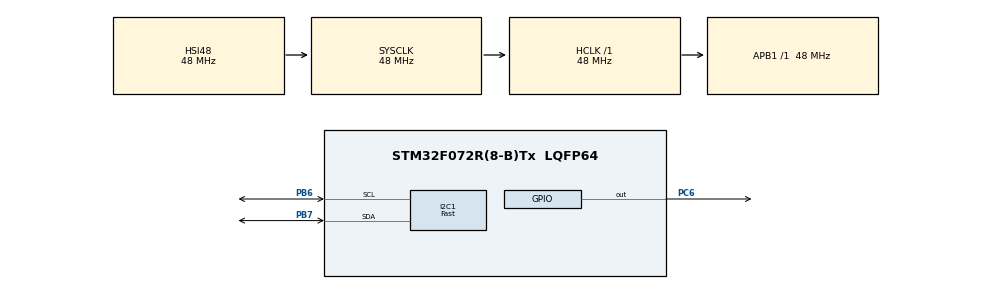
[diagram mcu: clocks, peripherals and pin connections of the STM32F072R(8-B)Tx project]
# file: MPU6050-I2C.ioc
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I2C1.I2C_Speed_Mode=I2C_Fast
I2C1.Timing=0x2010091A
Mcu.Family=STM32F0
Mcu.Name=STM32F072R(8-B)Tx
Mcu.Package=LQFP64
PB6.Mode=I2C
PB6.Signal=I2C1_SCL
PB7.Mode=I2C
PB7.Signal=I2C1_SDA
PC6.Signal=GPIO_Output
ProjectManager.HeapSize=0x200
ProjectManager.StackSize=0x400
ProjectManager.TargetToolchain=EWARM
RCC.AHBFreq_Value=48000000
RCC.APB1Freq_Value=48000000
RCC.APB1TimFreq_Value=48000000
RCC.HCLKFreq_Value=48000000
RCC.I2c1ClockSelection=RCC_I2C1CLKSOURCE_SYSCLK
RCC.PLLDivider=RCC_PREDIV_DIV2
RCC.PLLSourceVirtual=RCC_PLLSOURCE_HSI48
RCC.SYSCLKFreq_VALUE=48000000
RCC.SYSCLKSource=RCC_SYSCLKSOURCE_HSI48
board=MPU6050-I2C

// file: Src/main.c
/**
  ******************************************************************************
  * File Name          : main.c
  * Description        : Main program body
  ******************************************************************************
  *
  * COPYRIGHT(c) 2017 STMicroelectronics
  *
  * Redistribution and use in source and binary forms, with or without modification,
  * are permitted provided that the following conditions are met:
  *   1. Redistributions of source code must retain the above copyright notice,
  *      this list of conditions and the following disclaimer.
  *   2. Redistributions in binary form must reproduce the above copyright notice,
  *      this list of conditions and the following disclaimer in the documentation
  *      and/or other materials provided with the distribution.
  *   3. Neither the name of STMicroelectronics nor the names of its contributors
  *      may be used to endorse or promote products derived from this software
  *      without specific prior written permission.
  *
  * THIS SOFTWARE IS PROVIDED BY THE COPYRIGHT HOLDERS AND CONTRIBUTORS "AS IS"
  * AND ANY EXPRESS OR IMPLIED WARRANTIES, INCLUDING, BUT NOT LIMITED TO, THE
  * IMPLIED WARRANTIES OF MERCHANTABILITY AND FITNESS FOR A PARTICULAR PURPOSE ARE
  * DISCLAIMED. IN NO EVENT SHALL THE COPYRIGHT HOLDER OR CONTRIBUTORS BE LIABLE
  * FOR ANY DIRECT, INDIRECT, INCIDENTAL, SPECIAL, EXEMPLARY, OR CONSEQUENTIAL
  * DAMAGES (INCLUDING, BUT NOT LIMITED TO, PROCUREMENT OF SUBSTITUTE GOODS OR
  * SERVICES; LOSS OF USE, DATA, OR PROFITS; OR BUSINESS INTERRUPTION) HOWEVER
  * CAUSED AND ON ANY THEORY OF LIABILITY, WHETHER IN CONTRACT, STRICT LIABILITY,
  * OR TORT (INCLUDING NEGLIGENCE OR OTHERWISE) ARISING IN ANY WAY OUT OF THE USE
  * OF THIS SOFTWARE, EVEN IF ADVISED OF THE POSSIBILITY OF SUCH DAMAGE.
  *
  ******************************************************************************
  */
#include "main.h"
#include "stm32f0xx_hal.h"

/* USER CODE BEGIN Includes */
#include	"MPU_60X0.h"
/* USER CODE END Includes */

I2C_HandleTypeDef hi2c1;

/* USER CODE BEGIN PV */
/* Private variables ---------------------------------------------------------*/
volatile uint8_t Who_am_I;
volatile float temperature;
volatile MPU60X0_Data acc,gyro;
MPU60X0 MY_MPU(&hi2c1);

/* USER CODE END PV */

void SystemClock_Config(void);
void Error_Handler(void);
static void MX_GPIO_Init(void);
static void MX_I2C1_Init(void);

/* USER CODE BEGIN PFP */
/* Private function prototypes -----------------------------------------------*/

/* USER CODE END PFP */

int main(void)
{

  /* MCU Configuration----------------------------------------------------------*/

  /* Reset of all peripherals, Initializes the Flash interface and the Systick. */
  HAL_Init();

  /* Configure the system clock */
  SystemClock_Config();

  /* Initialize all configured peripherals */
  MX_GPIO_Init();
  MX_I2C1_Init();

  /* USER CODE BEGIN 2 */
  MY_MPU.Initialize(MPU60X0_Accelerometer_2G,MPU60X0_Gyroscope_250s);

  Who_am_I = MY_MPU.Who_am_I();
  /* USER CODE END 2 */

  /* Infinite loop */
  /* USER CODE BEGIN WHILE */
  while (1)
  {
    MY_MPU.Get_Accelerometer_value((MPU60X0_Data*)&acc);
    MY_MPU.Get_Gyroscope_value((MPU60X0_Data*)&gyro);

    //temperature =  MY_MPU.Get_Temperature();
    HAL_Delay(200);

  /* USER CODE END WHILE */

  }

}

/** System Clock Configuration
*/
void SystemClock_Config(void)
{

  RCC_OscInitTypeDef RCC_OscInitStruct;
  RCC_ClkInitTypeDef RCC_ClkInitStruct;
  RCC_PeriphCLKInitTypeDef PeriphClkInit;

    /**Initializes the CPU, AHB and APB busses clocks
    */
  RCC_OscInitStruct.OscillatorType = RCC_OSCILLATORTYPE_HSI48;
  RCC_OscInitStruct.HSI48State = RCC_HSI48_ON;
  RCC_OscInitStruct.PLL.PLLState = RCC_PLL_NONE;
  if (HAL_RCC_OscConfig(&RCC_OscInitStruct) != HAL_OK)
  {
    Error_Handler();
  }

    /**Initializes the CPU, AHB and APB busses clocks
    */
  RCC_ClkInitStruct.ClockType = RCC_CLOCKTYPE_HCLK|RCC_CLOCKTYPE_SYSCLK
                              |RCC_CLOCKTYPE_PCLK1;
  RCC_ClkInitStruct.SYSCLKSource = RCC_SYSCLKSOURCE_HSI48;
  RCC_ClkInitStruct.AHBCLKDivider = RCC_SYSCLK_DIV1;
  RCC_ClkInitStruct.APB1CLKDivider = RCC_HCLK_DIV1;

  if (HAL_RCC_ClockConfig(&RCC_ClkInitStruct, FLASH_LATENCY_1) != HAL_OK)
  {
    Error_Handler();
  }

  PeriphClkInit.PeriphClockSelection = RCC_PERIPHCLK_I2C1;
  PeriphClkInit.I2c1ClockSelection = RCC_I2C1CLKSOURCE_SYSCLK;
  if (HAL_RCCEx_PeriphCLKConfig(&PeriphClkInit) != HAL_OK)
  {
    Error_Handler();
  }

    /**Configure the Systick interrupt time
    */
  HAL_SYSTICK_Config(HAL_RCC_GetHCLKFreq()/1000);

    /**Configure the Systick
    */
  HAL_SYSTICK_CLKSourceConfig(SYSTICK_CLKSOURCE_HCLK);

  /* SysTick_IRQn interrupt configuration */
  HAL_NVIC_SetPriority(SysTick_IRQn, 0, 0);
}

/* I2C1 init function */
static void MX_I2C1_Init(void)
{

  hi2c1.Instance = I2C1;
  hi2c1.Init.Timing = 0x2010091A;
  hi2c1.Init.OwnAddress1 = 0;
  hi2c1.Init.AddressingMode = I2C_ADDRESSINGMODE_7BIT;
  hi2c1.Init.DualAddressMode = I2C_DUALADDRESS_DISABLE;
  hi2c1.Init.OwnAddress2 = 0;
  hi2c1.Init.OwnAddress2Masks = I2C_OA2_NOMASK;
  hi2c1.Init.GeneralCallMode = I2C_GENERALCALL_DISABLE;
  hi2c1.Init.NoStretchMode = I2C_NOSTRETCH_DISABLE;
  if (HAL_I2C_Init(&hi2c1) != HAL_OK)
  {
    Error_Handler();
  }

    /**Configure Analogue filter
    */
  if (HAL_I2CEx_ConfigAnalogFilter(&hi2c1, I2C_ANALOGFILTER_ENABLE) != HAL_OK)
  {
    Error_Handler();
  }

}

/** Configure pins as
        * Analog
        * Input
        * Output
        * EVENT_OUT
        * EXTI
*/
static void MX_GPIO_Init(void)
{

  GPIO_InitTypeDef GPIO_InitStruct;

  /* GPIO Ports Clock Enable */
  __HAL_RCC_GPIOC_CLK_ENABLE();
  __HAL_RCC_GPIOB_CLK_ENABLE();

  /*Configure GPIO pin Output Level */
  HAL_GPIO_WritePin(GPIOC, GPIO_PIN_6, GPIO_PIN_RESET);

  /*Configure GPIO pin : PC6 */
  GPIO_InitStruct.Pin = GPIO_PIN_6;
  GPIO_InitStruct.Mode = GPIO_MODE_OUTPUT_PP;
  GPIO_InitStruct.Pull = GPIO_NOPULL;
  GPIO_InitStruct.Speed = GPIO_SPEED_FREQ_LOW;
  HAL_GPIO_Init(GPIOC, &GPIO_InitStruct);

}

void Error_Handler(void)
{
  while(1)
  {
  }
}

/************************ (C) COPYRIGHT STMicroelectronics *****END OF FILE****/
